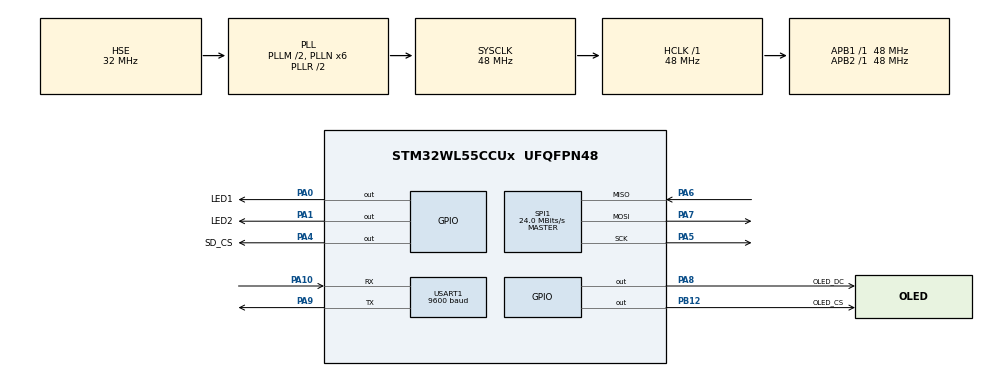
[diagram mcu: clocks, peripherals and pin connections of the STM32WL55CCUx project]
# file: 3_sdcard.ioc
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Dma.Request0=USART1_TX
Dma.USART1_TX.0.Channel_PRIV_NPRIV=DMA_CHANNEL_NPRIV_DISABLE
Dma.USART1_TX.0.Direction=DMA_MEMORY_TO_PERIPH
Dma.USART1_TX.0.EventEnable=DISABLE
Dma.USART1_TX.0.Instance=DMA1_Channel5
Dma.USART1_TX.0.MemDataAlignment=DMA_MDATAALIGN_BYTE
Dma.USART1_TX.0.MemInc=DMA_MINC_ENABLE
Dma.USART1_TX.0.Mode=DMA_NORMAL
Dma.USART1_TX.0.PeriphDataAlignment=DMA_PDATAALIGN_BYTE
Dma.USART1_TX.0.PeriphInc=DMA_PINC_DISABLE
Dma.USART1_TX.0.Polarity=HAL_DMAMUX_REQ_GEN_RISING
Dma.USART1_TX.0.Priority=DMA_PRIORITY_HIGH
Dma.USART1_TX.0.RequestNumber=1
Dma.USART1_TX.0.SignalID=NONE
Dma.USART1_TX.0.SyncEnable=DISABLE
Dma.USART1_TX.0.SyncPolarity=HAL_DMAMUX_SYNC_NO_EVENT
Dma.USART1_TX.0.SyncRequestNumber=1
Dma.USART1_TX.0.SyncSignalID=NONE
Mcu.Family=STM32WL
Mcu.Name=STM32WL55CCUx
Mcu.Package=UFQFPN48
NVIC.DMA1_Channel5_IRQn=true\:0\:0\:false\:false\:true\:false\:true\:true
NVIC.PriorityGroup=NVIC_PRIORITYGROUP_4
NVIC.USART1_IRQn=true\:0\:0\:false\:false\:true\:true\:true\:true
OSC_IN.Mode=HSE-External-Oscillator
OSC_IN.Signal=RCC_OSC_IN
OSC_OUT.Mode=HSE-External-Oscillator
OSC_OUT.Signal=RCC_OSC_OUT
PA0.GPIO_Label=LED1
PA0.Signal=GPIO_Output
PA1.GPIO_Label=LED2
PA1.Signal=GPIO_Output
PA10.Mode=Asynchronous
PA10.Signal=USART1_RX
PA4.GPIO_Label=SD_CS
PA4.GPIO_ModeDefaultOutputPP=GPIO_MODE_OUTPUT_OD
PA4.GPIO_PuPd=GPIO_NOPULL
PA4.GPIO_Speed=GPIO_SPEED_FREQ_VERY_HIGH
PA4.PinState=GPIO_PIN_SET
PA4.Signal=GPIO_Output
PA5.Mode=Full_Duplex_Master
PA5.Signal=SPI1_SCK
PA6.Mode=Full_Duplex_Master
PA6.Signal=SPI1_MISO
PA7.Mode=Full_Duplex_Master
PA7.Signal=SPI1_MOSI
PA8.GPIO_Label=OLED_DC
PA8.GPIO_ModeDefaultOutputPP=GPIO_MODE_OUTPUT_OD
PA8.GPIO_PuPd=GPIO_NOPULL
PA8.GPIO_Speed=GPIO_SPEED_FREQ_VERY_HIGH
PA8.Signal=GPIO_Output
PA9.Mode=Asynchronous
PA9.Signal=USART1_TX
PB12.GPIO_Label=OLED_CS
PB12.Signal=GPIO_Output
PC14-OSC32_IN.Mode=LSE-External-Oscillator
PC14-OSC32_IN.Signal=RCC_OSC32_IN
PC15-OSC32_OUT.Mode=LSE-External-Oscillator
PC15-OSC32_OUT.Signal=RCC_OSC32_OUT
ProjectManager.HeapSize=0x200
ProjectManager.StackSize=0x400
ProjectManager.TargetToolchain=MDK-ARM V5.37
RCC.AHBFreq_Value=48000000
RCC.APB1Freq_Value=48000000
RCC.APB1TimFreq_Value=48000000
RCC.APB2Freq_Value=48000000
RCC.APB2TimFreq_Value=48000000
RCC.APB3Freq_Value=48000000
RCC.CortexFreq_Value=48000000
RCC.HCLKFreq_Value=48000000
RCC.HSE_VALUE=32000000
RCC.HSI_VALUE=16000000
RCC.LSE_VALUE=32768
RCC.MSIClockRange=RCC_MSIRANGE_11
RCC.PLLM=RCC_PLLM_DIV2
RCC.PLLN=6
RCC.PLLSourceVirtual=RCC_PLLSOURCE_HSE
RCC.SYSCLKFreq_VALUE=48000000
RCC.SYSCLKSource=RCC_SYSCLKSOURCE_PLLCLK
RCC.VCOOutputFreq_Value=96000000
SPI1.CLKPhase=SPI_PHASE_2EDGE
SPI1.CLKPolarity=SPI_POLARITY_HIGH
SPI1.CRCCalculation=SPI_CRCCALCULATION_DISABLE
SPI1.CalculateBaudRate=24.0 MBits/s
SPI1.DataSize=SPI_DATASIZE_8BIT
SPI1.Direction=SPI_DIRECTION_2LINES
SPI1.Mode=SPI_MODE_MASTER
SPI1.VirtualType=VM_MASTER
USART1.BaudRate=9600
USART1.ClockPrescaler=PRESCALER_DIV1
USART1.FIFOMode=FIFOMODE_ENABLE
USART1.RXFIFOThreshold=RXFIFO_THRESHOLD_HALFFULL
USART1.TXFIFOThreshold=TXFIFO_THRESHOLD_HALFFULL
USART1.VirtualMode-Asynchronous=VM_ASYNC
board=custom

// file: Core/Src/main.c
/* USER CODE BEGIN Header */
/**
  ******************************************************************************
  * @file           : main.c
  * @brief          : Main program body
  ******************************************************************************
  * @attention
  *
  * Copyright (c) 2024 STMicroelectronics.
  * All rights reserved.
  *
  * This software is licensed under terms that can be found in the LICENSE file
  * in the root directory of this software component.
  * If no LICENSE file comes with this software, it is provided AS-IS.
  *
  ******************************************************************************
  */
/* USER CODE END Header */
#include "main.h"
#include "dma.h"
#include "spi.h"
#include "usart.h"
#include "gpio.h"

/* USER CODE BEGIN Includes */
#include "user.h"
/* USER CODE END Includes */

void SystemClock_Config(void);

int main(void)
{

  /* MCU Configuration--------------------------------------------------------*/

  /* Reset of all peripherals, Initializes the Flash interface and the Systick. */
  HAL_Init();

  /* Configure the system clock */
  SystemClock_Config();

  /* Initialize all configured peripherals */
  MX_GPIO_Init();
  MX_DMA_Init();
  MX_USART1_UART_Init();
  MX_SPI1_Init();
  /* USER CODE BEGIN 2 */
  user_setup();
  /* USER CODE END 2 */

  /* Infinite loop */
  /* USER CODE BEGIN WHILE */
  while (1)
  {
    user_loop();
    /* USER CODE END WHILE */

  }
}

void SystemClock_Config(void)
{
  RCC_OscInitTypeDef RCC_OscInitStruct = {0};
  RCC_ClkInitTypeDef RCC_ClkInitStruct = {0};

  /** Configure the main internal regulator output voltage
  */
  __HAL_PWR_VOLTAGESCALING_CONFIG(PWR_REGULATOR_VOLTAGE_SCALE1);

  /** Initializes the CPU, AHB and APB buses clocks
  */
  RCC_OscInitStruct.OscillatorType = RCC_OSCILLATORTYPE_HSE;
  RCC_OscInitStruct.HSEState = RCC_HSE_ON;
  RCC_OscInitStruct.HSEDiv = RCC_HSE_DIV1;
  RCC_OscInitStruct.PLL.PLLState = RCC_PLL_ON;
  RCC_OscInitStruct.PLL.PLLSource = RCC_PLLSOURCE_HSE;
  RCC_OscInitStruct.PLL.PLLM = RCC_PLLM_DIV2;
  RCC_OscInitStruct.PLL.PLLN = 6;
  RCC_OscInitStruct.PLL.PLLP = RCC_PLLP_DIV2;
  RCC_OscInitStruct.PLL.PLLR = RCC_PLLR_DIV2;
  RCC_OscInitStruct.PLL.PLLQ = RCC_PLLQ_DIV2;
  if (HAL_RCC_OscConfig(&RCC_OscInitStruct) != HAL_OK)
  {
    Error_Handler();
  }

  /** Configure the SYSCLKSource, HCLK, PCLK1 and PCLK2 clocks dividers
  */
  RCC_ClkInitStruct.ClockType = RCC_CLOCKTYPE_HCLK3|RCC_CLOCKTYPE_HCLK
                              |RCC_CLOCKTYPE_SYSCLK|RCC_CLOCKTYPE_PCLK1
                              |RCC_CLOCKTYPE_PCLK2;
  RCC_ClkInitStruct.SYSCLKSource = RCC_SYSCLKSOURCE_PLLCLK;
  RCC_ClkInitStruct.AHBCLKDivider = RCC_SYSCLK_DIV1;
  RCC_ClkInitStruct.APB1CLKDivider = RCC_HCLK_DIV1;
  RCC_ClkInitStruct.APB2CLKDivider = RCC_HCLK_DIV1;
  RCC_ClkInitStruct.AHBCLK3Divider = RCC_SYSCLK_DIV1;

  if (HAL_RCC_ClockConfig(&RCC_ClkInitStruct, FLASH_LATENCY_2) != HAL_OK)
  {
    Error_Handler();
  }
}

void Error_Handler(void)
{
  __disable_irq();
  while (1)
  {
  }
}
